# NANO103AE_v1 register map
File version: 1.0
Registers are 32-bit, read-write, reset 0x0 unless marked. A register's access mark holds for its fields unless they carry their own. Offsets are from the block's base; [hi:lo] are bit positions; {n}, {i} and the like mark numbered series; 'fields as' and 'values as' point back to an identical list.

## TMR01 — TMR Register Map
Base 0x40010000
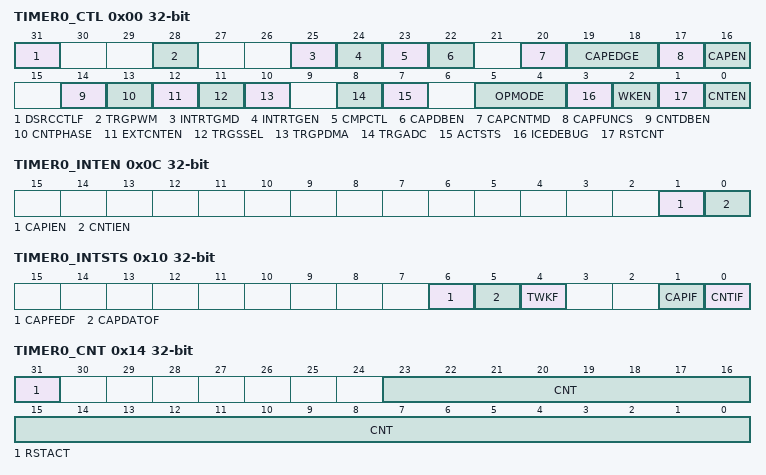
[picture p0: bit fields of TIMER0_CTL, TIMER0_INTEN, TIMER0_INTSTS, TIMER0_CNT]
0x00 TIMER0_CTL — Timer 0 Control and Status Register
  [31] DSRCCTLF ro — DSRC Control Timer Flag (Read Only). This flag high indicates this timer is being controlled by DSRC. When DSRCCTLF is 1, write operation to register of this timer wouldn't take any effect. Note1:This bit is read only. Write operation wouldn't take any effect. Note2: This bit is only valid in Timer2. In Timer0, Timer1 and Timer3, read this bit always get 0.
    0=DSRC control Timer Disabled; 1=DSRC control Timer Enabled
  [28] TRGPWM — Trigger PWM EnableBit. If this bit is set to 1, timer time-out interrupt or capture interrupt can trigger PWM.
    0=Timer interrupt trigger PWM Disabled; 1=Timer interrupt trigger PWM Enabled
  [25] INTRTGMD — Inter-timer Trigger Mode Selection. Note:In TIMERx+1_CTL, this bit is always 0.
    0=TIMERx count the all input events from Tx pin; 1=TIMERx ignored the number of first incoming events based on EVNTDPCNT (TIMERx_ECTL[31:24])
  [24] INTRTGEN — Inter-timer Trigger Function EnableBit. Note:In TIMERx+1_CTL, this bit is always 0.
    0=Inter-timer trigger function Disabled; 1=Inter-timer trigger function Enabled
  [23] CMPCTL — Timer Compared Mode Selection. If updated CMPDAT (TIMERx_CMP) value CNT (TIMERx_CNT), CNT (TIMERx_CNT) will be reset to default value. At the same time, prescale counter reloaded.
    0=The behavior selection in one-shot, periodic or Toggle-output mode Disabled; 1=The behavior selection in one-shot, periodic or Toggle-output mode Enabled
  [22] CAPDBEN — Timer External Capture Pin De-bounce Enable Bit. Note1: If this bit is enabled, the edge detection of Tx_EXT pin is detected with de-bounce circuit. Note2: For Timer 1 and 3, when INTRTGEN (TIMERx_CTL[24]) is high, the capture signal is from internal of chip and the de-bounce circuit would not take effect no matter this bit is high or low.
    0=Tx_EXT (x= 0~3) pin de-bounce Disabled; 1=Tx_EXT (x= 0~3) pin de-bounce Enabled
  [20] CAPCNTMD — Timer Capture Counting Mode Selection. This bit indicates the behavior of 24-bit up-counting timer while CAPEN (TIMERx_CTL[16]) is set to high. If this bit is 0, the free-counting mode, the behavior of 24-bit up-counting timer is defined by OPMODE (TIMERx_CTL[5:4]) field. When CAPEN (TIMERx_CTL[16]) is set, CAPFUNCS (TIMERx_CTL[17]) is 0, and the transition of TC pin matches the CAPEDGE (TIMERx_CTL[19:18]) setting, the value of 24-bit up-counting timer will be saved into register TIMERx_CAP. If this bit is 1, Trigger-counting mode, 24-bit up-counting timer will be not counting and keep its value at 0. When CAPEN (TIMERx_CTL[16]) is set, CAPFUNCS (TIMERx_CTL[17]) is 0, and once the transition of external pin matches the 1st transition of CAPEDGE (TIMERx_CTL[19:18]) setting, the 24-bit up-counting timer will start counting. And then if the transition of external pin matches the 2nd transition of CAPEDGE (TIMERx_CTL[19:18]) setting, the 24-bit up-counting timer will stop counting. And its value will be saved into register TIMERx_CAP.
    0=Capture with free-counting timer mode; 1=Capture with trigger-counting timer mode
  [19:18] CAPEDGE — Timer External Capture Pin Edge Detection. For timer counter reset function and free-counting mode of timer capture function, the configurations are:
    0=A Falling edge on Tx_EXT (x= 0~3) pin will be detected. 1stfalling edge on TC pin triggers 24-bit timer to start counting, while 2nd falling edge triggers 24-bit timer to stop counting; 1=A Rising edge on Tx_EXT (x= 0~3) pin will be detected. 1st rising edge on TC pin triggers 24-bit timer to start counting, while 2nd rising edge triggers 24-bit timer to stop counting; 2=Either Rising or Falling edge on Tx_EXT (x= 0~3) pin will be detected. Falling edge on TC pin triggers 24-bit timer to start counting, while rising edge triggers 24-bit timer to stop counting; 3=Either Rising or Falling edge on Tx_EXT (x= 0~3) pin will be detected. Rising edge on TC pin triggers 24-bit timer to start counting, while falling edge triggers 24-bit timer to stop counting
  [17] CAPFUNCS — Capture Function Selection
    0=External Capture Mode Enabled; 1=External Reset Mode Enabled
  [16] CAPEN — Timer External Capture Pin Enable Bit. This bit enables the Tx_EXT pin.
    0=Tx_EXT (x= 0~3) pin Disabled; 1=Tx_EXT (x= 0~3) pin Enabled
  [14] CNTDBEN — Timer Counter Pin De-bounce Enable Bit. Note: If this bit is set to 1, the edge detection of Tx pin is detected with de-bounce circuit.
    0=Tx (x= 0~3) pin de-bounce Disabled; 1=Tx (x= 0~3) pin de-bounce Enabled
  [13] CNTPHASE — Timer External Count Phase
    0=A Falling edge of external counting pin will be counted; 1=A Rising edge of external counting pin will be counted
  [12] EXTCNTEN — Event Counter Mode Enable Bit. This bit is for external counting pin function enabled. Note: When timer is used as an event counter, this bit should be set to 1 and HCLK as timer clock source.
    0=Event counter mode Disabled; 1=Event counter mode Enabled
  [11] TRGSSEL — Trigger Source Selection. If this bit is set to 1, capture interrupt can trigger ADC, PDMA and PWM. Otherwise, time-out interrupt can trigger ADC, PDMA and PWM.
    0=Time-out interrupt is used to trigger ADC, PDMA and PWM; 1=Capture interrupt is used to trigger ADC, PDMA and PWM
  [10] TRGPDMA — Timer Trigger PDMA EnableBit. If this bit is set to 1, timer time-out interrupt or capture interrupt can trigger PDMA. Note: If TRGSSEL (TIMERx_CTL[11]) is set to 0, the time-out interrupt signal will trigger PDMA. If TRGSSEL (TIMERx_CTL[11]) is set to 1, the capture interrupt signal will trigger PDMA.
    0=Timer interrupt trigger PDMADisabled; 1=Timer interrupt trigger PDMAEnabled
  [8] TRGADC — Trigger ADC Enable Bit. If this bit is set to 1, timer time-out interrupt or capture interrupt can trigger ADC. Note: If TRGSSEL (TIMERx_CTL[11]) is set to 0, the time-out interrupt signal will trigger ADC. If TRGSSEL (TIMERx_CTL[11]) is set to 1, the capture interrupt signal will trigger ADC.
    0=Timer interrupt trigger ADC Disabled; 1=Timer interrupt trigger ADC Enabled
  [7] ACTSTS ro — Timer Active Status Bit (Read Only). This bit indicates the 24-bit up counter status.
    0=24-bit up counter is not active; 1=24-bit up counter is active
  [5:4] OPMODE — Timer Counting Mode Selection
    0=The Timer controller is operated in One-shot mode; 1=The Timer controller is operated in Periodic mode; 2=The Timer controller is operated in Toggle-output mode; 3=The Timer controller is operated in Continuous Counting mode
  [3] ICEDEBUG — ICE Debug Mode Acknowledge Disable Bit. Timer counter will keep going no matter CPU is held by ICE or not.
    0=ICE debug mode acknowledgement affects TIMER counting; 1=ICE debug mode acknowledgement Disabled
  [2] WKEN — Wake-up Function Enable Bit. If this bit is set to 1, while CNTIF (TIMERx_INTSTS[0]) or CAPIF (TIMERx_INTSTS[1]) is 1, the timer interrupt signal will generate a wake-up trigger event to CPU.
    0=Wake-up function Disabled if timer interrupt signal generated; 1=Wake-up function Enabled if timer interrupt signal generated
  [1] RSTCNT — Timer Counter Reset Bit. Setting this bit will reset the internal 8-bit prescale counter, 24-bit up counter value CNT (TIMERx_CNT[23:0]) and also force CNTEN (TIMERx_CTL[0]) to 0. Note: This bit will be auto cleared and takes at least 3 TIMERx_CLK clock cycles.
    0=No effect; 1=Reset internal 8-bit prescale counter, 24-bit up counter value and CNTEN bit
  [0] CNTEN — Timer Counting Enable Bit. Note3: Writing this bit 1 will not take any effect if RSTCNT (TIMERx_CTL[1]) is also set to 1 at the same time.
    0=Stops/Suspends counting; 1=Starts counting
0x04 TIMER0_PRECNT — Timer 0 Pre-Scale Counter Register
  [7:0] PSC — Prescale Counter. Note: If the PSC value is changed, CNT (TIMERx_CNT) is reset to 0 and prescale counter is reloaded.
0x08 TIMER0_CMP — Timer 0 Compare Register
  [23:0] CMPDAT — Timer Compared Value. CMPDAT is a 24-bit compared value register. When the internal 24-bit up counter value is equal to CMPDAT value, the CNTIF (TIMERx_INTSTS[0] Timer Interrupt Flag) will be set to 1. Note1: Never write 0x0 or 0x1 in CMPDAT, or the core will run into unknown state. Note2:When the timer is operating in Continuous Counting mode (OPMODE (TIMERx_CTL[5:4] is 11), the 24-bit up counter will keep counting continuously even if user writes a new value into CMPDAT field. Note3: Whenthe timer is not operating inContinuous Counting mode (OPMODE (TIMERx_CTL[5:4] is not 11), the 24-bit up counter will restart counting from 0 and usethe newest CMPDAT value as the timer compared value when user writes a new value into the CMPDAT field.In addition, the prescale counter will be reloaded.
0x0C TIMER0_INTEN — Timer 0 Interrupt Enable Register
  [1] CAPIEN — Timer External Capture Interrupt Enable Bit. Note:CAPIEN is used to enable timer external interrupt. If CAPIEN is enabled, the timer will rise an interrupt when CAPIF (TIMERx_INTSTS[1]) is 1.
    0=Tx_EXT (x= 0~3) pin detection Interrupt Disabled; 1=Tx_EXT (x= 0~3) pin detection Interrupt Enabled
  [0] CNTIEN — Timer Interrupt EnableBit. Note:If this bit is enabled, when the timer interrupt flag CNTIF(TIMERx_INTSTS[0]) is set to 1, the timer interrupt signal is generated and informed to CPU.
    0=Timer Interrupt Disabled; 1=Timer Interrupt Enabled
0x10 TIMER0_INTSTS — Timer 0 Interrupt Status Register
  [6] CAPFEDF — Capture Falling Edge Detected Flag. This flag indicates theedge detected on Tx_EXT pin is rising edge or falling edge. Note1: The timer updates this flag when it updates the Timer Capture Data (TMR_CAP[23:0]) value. Note2:When a new incoming capture event detected before CPU clearing the CAPIF (TIMERx_INTSTS[1]) status, Timer will keep this bit unchanged.
    0=Rising edge detected on Tx_EXT pin; 1=Falling edge detected on Tx_EXT pin
  [5] CAPDATOF — Capture Data Overflow Flag. This status is to indicate there is a new incoming capture event detected before CPU clearing the CAPIF (TIMERx_INTSTS[1]) status. If the above condition occurred, the Timer will keep register TIMERx_CAP unchanged and drop the new capture value. Note: This bit is cleared by writing 1 to it.
    0=New incoming capture event didn't detect before CPU clearing CAPIF (TIMERx_INTSTS[1]) status; 1=New incoming capture event detected before CPU clearing CAPIF (TIMERx_INTSTS[1]) status
  [4] TWKF — Timer Wake-up Flag. This bit indicates the interrupt wake-up flag status of timer. Note: This bit is cleared by writing 1 to it.
    0=Timer does not cause CPU wake-up; 1=CPU wake-up from Idle or Power-down mode if timer time-out interrupt signal generated
  [1] CAPIF — Timer External Capture Interrupt Flag. This bit indicates the timer external capture interrupt flag status. Note3: If a new incoming capture event detected before CPU clearing the CAPIF status, the Timer will keep register TIMERx_CAP unchanged and drop the new capture value.
    0=Tx_EXT (x= 0~3) pin interrupt did not occur; 1=Tx_EXT (x= 0~3) pin interrupt occurred
  [0] CNTIF — Timer Interrupt Status. This bit indicates the interrupt flag status of Timer while 24-bit timer up counter CNT (TIMERx_CNT[23:0]) value reaches to CMPDAT (TIMERx_CMP[23:0]) value. Note: This bit is cleared by writing 1 to it.
    0=No effect; 1=CNT (TIMERx_CNT[23:0])value matches the CMPDAT (TIMERx_CMP[23:0]) value
0x14 TIMER0_CNT — Timer 0Counter Data Register
  [31] RSTACT — Reset Active. This bit indicates if the counter reset operation active. When user write this register, timer starts to reset its internal 24-bit timer up-counter and 8-bit pre-scale counter to 0. At the same time, timer set this flag to 1 to indicate the counter reset operation is in progress. Once the counter reset operation done, timer clear this bit to 0 automatically. Note: This bit is read only. Write operation wouldn't take any effect.
    0=Reset operation is done; 1=Reset operation triggered by writing TIMERx_CNT is in progress
  [23:0] CNT — Timer Counter Data (Read). Counter Reset (Write). User can write any value to TIEMRx_CNT to reset internal 24-bit timer up-counter and 8-bit pre-scale counter. This reset operation wouldn't affect any other timer control registers and circuit. After reset completed, the 24-bit timer up-counter and 8-bit pre-scale counter restart the counting based on the TIMERx_CTL register setting.
0x18 TIMER0_CAP ro — Timer 0 Capture Data Register
  [23:0] CAPDAT — Timer Capture Data Register. When CAPEN (TIMERx_CTL[16]) bit is set, CAPFUNCS (TIMERx_CTL[17]) bit is 0, CAPCNTMD (TIMERx_CTL[20]) bit is 0, and the transition on Tx_EXT pin matched the CAPEDGE (TIMERx_CTL[19:18]) setting, CAPIF (TIMERx_INTSTS[1]) will set to 1 and the current timer counter value CNT (TIMERx_CNT[23:0]) will be auto-loaded into this CAPDAT field. When CAPEN (TIMERx_CTL[16]) bit is set, CAPFUNCS (TIMERx_CTL[17]) bit is 0, CAPCNTMD (TIMERx_CTL[20]) bit is 1, and the transition on Tx_EXT pin matched the 2nd transition of CAPEDGE (TIMERx_CTL[19:18]) setting, CAPIF (TIMERx_INTSTS[1]) will set to 1 and the current timer counter value CNT (TIMERx_CNT[23:0]) will be auto-loaded into this CAPDAT field.
0x20 TIMER0_ECTL — Timer 0Extended Control Register
  [31:24] EVNTDPCNT — Event Drop Count. This field indicates timer how many events dropped after inter-timer trigger function enable. For example, if user configured EVNTDPCNT to 7, timer would drop 7 first incoming events and starts the inter-timer trigger operation when it get 8th event. Note: ECNTDPCNT only takes effect when INTRTGEN (TIMERx_CTL[24]) INTRTGMD (TIMERx_CTL[25]) are both set to 1.
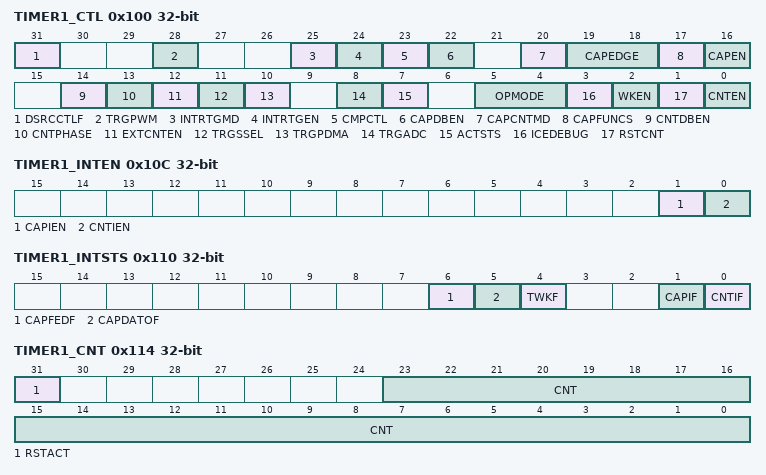
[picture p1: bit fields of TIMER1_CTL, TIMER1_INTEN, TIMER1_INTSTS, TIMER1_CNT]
0x100 TIMER1_CTL — Timer 1 Control and Status Register
  fields as TIMER0_CTL
0x104 TIMER1_PRECNT — Timer 1 Pre-Scale Counter Register
  fields as TIMER0_PRECNT
0x108 TIMER1_CMP — Timer 1 Compare Register
  fields as TIMER0_CMP
0x10C TIMER1_INTEN — Timer 1 Interrupt Enable Register
  fields as TIMER0_INTEN
0x110 TIMER1_INTSTS — Timer 1 Interrupt Status Register
  fields as TIMER0_INTSTS
0x114 TIMER1_CNT — Timer 1 Counter Data Register
  fields as TIMER0_CNT
0x118 TIMER1_CAP ro — Timer 1 Capture Data Register
  fields as TIMER0_CAP
0x120 TIMER1_ECTL — Timer 1 Extended Control Register
  fields as TIMER0_ECTL
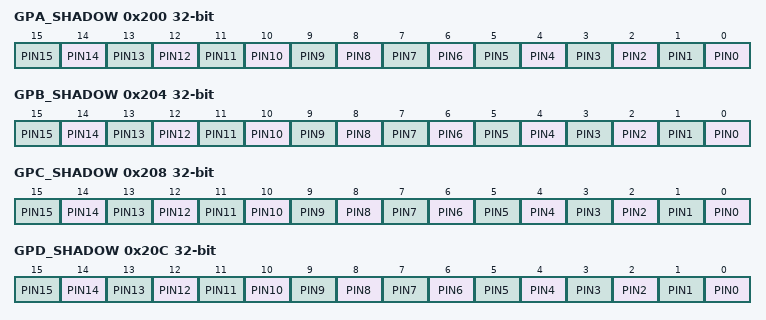
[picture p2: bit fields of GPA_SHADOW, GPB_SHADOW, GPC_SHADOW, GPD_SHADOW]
0x200 GPA_SHADOW ro (reset mask 0xFFFF0000) — GPIO Port A Pin Value Shadow Register
  [n] PIN{n} (n=0..15) — GPIO Port [A/B/C/D/E/F] Pin Values. The value read from each of these bit reflects the actual status of the respective GPIO pin. These registers are shadow registers of GPIOx_PIN register. Note 1: For GPE_SHADOW, bits [15:10] are reserved. Note2: For GPF_SHADOW, bits [15:6] are reserved.
0x204 GPB_SHADOW ro (reset mask 0xFFFF0000) — GPIO Port B Pin Value Shadow Register
  fields as GPA_SHADOW
0x208 GPC_SHADOW ro (reset mask 0xFFFF0000) — GPIO Port C Pin Value Shadow Register
  fields as GPA_SHADOW
0x20C GPD_SHADOW ro (reset mask 0xFFFF0000) — GPIO Port D Pin Value Shadow Register
  fields as GPA_SHADOW
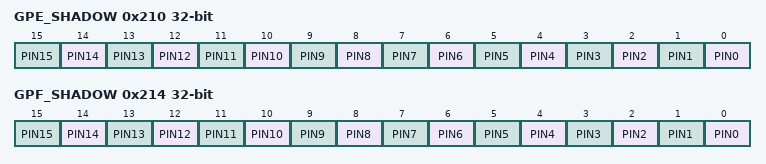
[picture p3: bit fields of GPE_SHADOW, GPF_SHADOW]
0x210 GPE_SHADOW ro (reset mask 0xFFFF0000) — GPIO Port E Pin Value Shadow Register
  fields as GPA_SHADOW
0x214 GPF_SHADOW ro (reset mask 0xFFFF0000) — GPIO Port F Pin Value Shadow Register
  fields as GPA_SHADOW
